# 3065ARPIRZ register map
File version: 1.0
Registers are 32-bit, access per field, reset 0x0 unless marked. A register's access mark holds for its fields unless they carry their own. Offsets are from the block's base; [hi:lo] are bit positions.

## IOCMG_ANA — IOCMG_ANA peripheral interface
Base 0x149F0000
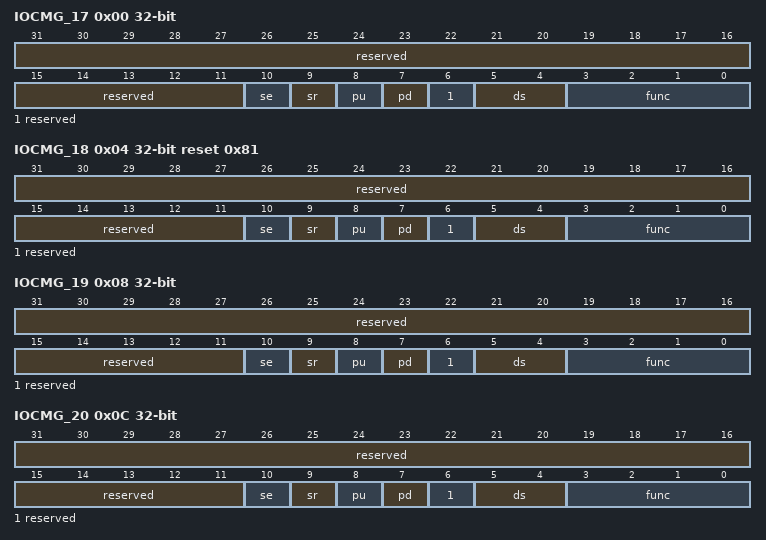
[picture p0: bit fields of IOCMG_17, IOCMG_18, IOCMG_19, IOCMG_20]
0x00 IOCMG_17 — QDM_INDEX/POE1 管脚配置寄存器。
  [31:11] reserved ro — 保留。
  [10] se rw — 管脚施密特输入控制。 0x0：关闭； 0x1：打开。
  [9] sr rw — 管脚电平转换速率控制。 0x0：快沿输出； 0x1：慢沿输出。
  [8] pu rw — 管脚上拉控制。 0x0：关闭； 0x1：打开。
  [7] pd rw — 管脚下拉控制。 0x0：关闭； 0x1：打开。
  [6] reserved ro — 保留。
  [5:4] ds rw — 管脚驱动能力选择（档位越大，驱动能力越大）。 00：档位4； 01：档位3； 10：档位2； 11：档位1。
  [3:0] func rw — 功能选择。 0x0: GPIO1_6； 0x1: QDM_INDEX； 0x2: POE1； 0x3: QDM_SYNC； 其它: 保留。
0x04 IOCMG_18 reset 0x81 — TRSTN/ADC1_B3/CAPM1 管脚配置寄存器。
  [31:11] reserved ro — 保留。
  [10] se rw — 管脚施密特输入控制。 0x0：关闭； 0x1：打开。
  [9] sr rw — 管脚电平转换速率控制。 0x0：快沿输出； 0x1：慢沿输出。
  [8] pu rw — 管脚上拉控制。 0x0：关闭； 0x1：打开。
  [7] pd rw — 管脚下拉控制： 0x0：关闭； 0x1：打开。
  [6] reserved ro — 保留。
  [5:4] ds rw — 管脚驱动能力选择（档位越大，驱动能力越大）。 00：档位4； 01：档位3； 10：档位2； 11：档位1。
  [3:0] func rw — 功能选择。 0x0: GPIO1_7； 0x1: JTAG_TRSTN； 0x3: CAPM1_SRC1； 0x4: UART1_CTSN； 0x5: SPI0_CSN0； 0x6: ADTRG1； 0x8: ADC1_ANA_B3； 0x9: ACMP1_ANA_N2； 其它: 保留。
0x08 IOCMG_19 — ADC1_B4/CAPM2 管脚配置寄存器。
  [31:11] reserved ro — 保留。
  [10] se rw — 管脚施密特输入控制。 0x0：关闭； 0x1：打开。
  [9] sr rw — 管脚电平转换速率控制。 0x0：快沿输出； 0x1：慢沿输出。
  [8] pu rw — 管脚上拉控制。 0x0：关闭； 0x1：打开。
  [7] pd rw — 管脚下拉控制。 0x0：关闭； 0x1：打开。
  [6] reserved ro — 保留。
  [5:4] ds rw — 管脚驱动能力选择（档位越大，驱动能力越大）。 00：档位4； 01：档位3； 10：档位2； 11：档位1。
  [3:0] func rw — 功能选择。 0x0: GPIO2_0； 0x3: CAPM2_SRC1； 0x5: SPI0_TXD； 0x8: ADC1_ANA_B4； 其它: 保留。
0x0C IOCMG_20 — ADC1_B5 管脚配置寄存器。
  [31:11] reserved ro — 保留。
  [10] se rw — 管脚施密特输入控制。 0x0：关闭； 0x1：打开。
  [9] sr rw — 管脚电平转换速率控制。 0x0：快沿输出； 0x1：慢沿输出。
  [8] pu rw — 管脚上拉控制。 0x0：关闭； 0x1：打开。
  [7] pd rw — 管脚下拉控制。 0x0：关闭； 0x1：打开。
  [6] reserved ro — 保留。
  [5:4] ds rw — 管脚驱动能力选择（档位越大，驱动能力越大）。 00：档位4； 01：档位3； 10：档位2； 11：档位1。
  [3:0] func rw — 功能选择。 0x0: GPIO2_1； 0x3: CAPM0_SRC1； 0x5: SPI0_RXD； 0x8: ADC1_ANA_B5； 其它: 保留。
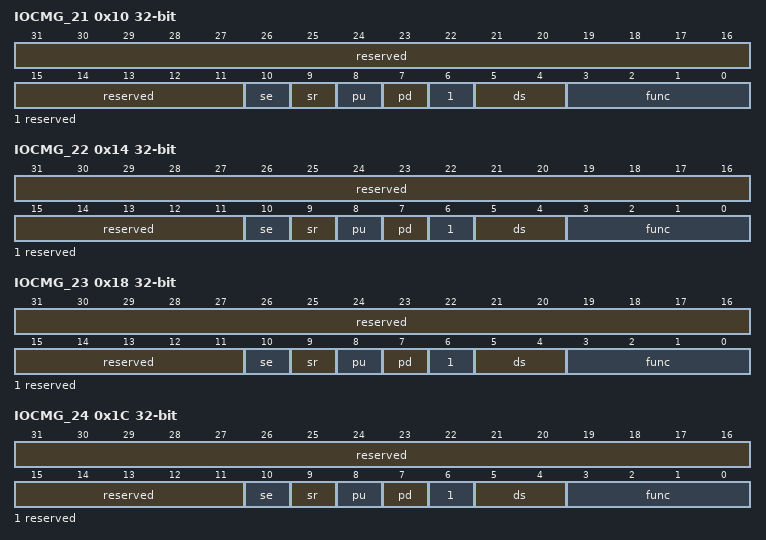
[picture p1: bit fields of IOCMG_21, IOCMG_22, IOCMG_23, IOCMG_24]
0x10 IOCMG_21 — ADC1_A1 管脚配置寄存器。
  [31:11] reserved ro — 保留。
  [10] se rw — 管脚施密特输入控制。 0x0：关闭； 0x1：打开。
  [9] sr rw — 管脚电平转换速率控制。 0x0：快沿输出； 0x1：慢沿输出。
  [8] pu rw — 管脚上拉控制。 0x0：关闭； 0x1：打开。
  [7] pd rw — 管脚下拉控制。 0x0：关闭； 0x1：打开。
  [6] reserved ro — 保留。
  [5:4] ds rw — 管脚驱动能力选择（档位越大，驱动能力越大）。 00：档位4； 01：档位3； 10：档位2； 11：档位1。
  [3:0] func rw — 功能选择。 0x0: GPIO2_2； 0x2: APT_EVTMP4； 0x4: UART1_RTSN； 0x5: SPI0_CSN1； 0x6: ADST1； 0x8: ADC1_ANA_A1； 0x9: ACMP1_ANA_P2； 其它: 保留。
0x14 IOCMG_22 — ADC1_A2/PGA1IN_P0 管脚配置寄存器。
  [31:11] reserved ro — 保留。
  [10] se rw — 管脚施密特输入控制。 0x0：关闭； 0x1：打开。
  [9] sr rw — 管脚电平转换速率控制。 0x0：快沿输出； 0x1：慢沿输出。
  [8] pu rw — 管脚上拉控制。 0x0：关闭； 0x1：打开。
  [7] pd rw — 管脚下拉控制。 0x0：关闭； 0x1：打开。
  [6] reserved ro — 保留。
  [5:4] ds rw — 管脚驱动能力选择（档位越大，驱动能力越大）。 00：档位4； 01：档位3； 10：档位2； 11：档位1。
  [3:0] func rw — 功能选择。 0x0: GPIO2_3； 0x5: SPI0_CLK； 0x8: ADC1_ANA_A2； 0x9: PGA1_ANA_P0； 其它: 保留。
0x18 IOCMG_23 — ADC1_B2/PGA1IN_N0/APT6_A 管脚配置寄存器。
  [31:11] reserved ro — 保留。
  [10] se rw — 管脚施密特输入控制。 0x0：关闭； 0x1：打开。
  [9] sr rw — 管脚电平转换速率控制。 0x0：快沿输出； 0x1：慢沿输出。
  [8] pu rw — 管脚上拉控制。 0x0：关闭； 0x1：打开。
  [7] pd rw — 管脚下拉控制。 0x0：关闭； 0x1：打开。
  [6] reserved ro — 保留。
  [5:4] ds rw — 管脚驱动能力选择（档位越大，驱动能力越大）。 00：档位4； 01：档位3； 10：档位2； 11：档位1。
  [3:0] func rw — 功能选择。 0x0: GPIO2_4； 0x3: APT6_PWMA； 0x8: ADC1_ANA_B2； 0x9: PGA1_ANA_N0； 其它: 保留。
0x1C IOCMG_24 — PGA1OUT0 管脚配置寄存器。
  [31:11] reserved ro — 保留。
  [10] se rw — 管脚施密特输入控制。 0x0：关闭； 0x1：打开。
  [9] sr rw — 管脚电平转换速率控制。 0x0：快沿输出； 0x1：慢沿输出。
  [8] pu rw — 管脚上拉控制。 0x0：关闭； 0x1：打开。
  [7] pd rw — 管脚下拉控制。 0x0：关闭； 0x1：打开。
  [6] reserved ro — 保留。
  [5:4] ds rw — 管脚驱动能力选择（档位越大，驱动能力越大）。 00：档位4； 01：档位3； 10：档位2； 11：档位1。
  [3:0] func rw — 功能选择。 0x0: GPIO2_5； 0x3: APT7_PWMA； 0x8: PGA1_ANA_EXT0； 其它: 保留。
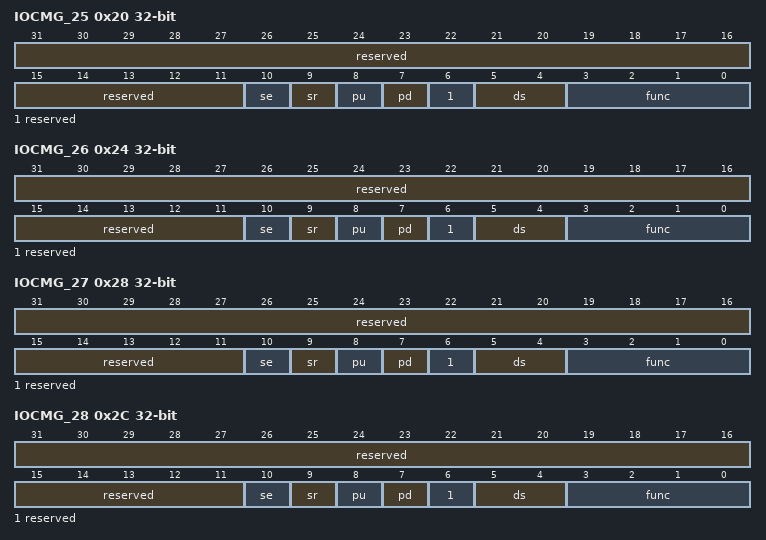
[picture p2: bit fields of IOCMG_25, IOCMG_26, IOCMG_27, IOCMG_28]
0x20 IOCMG_25 — ADC1_A3 管脚配置寄存器。
  [31:11] reserved ro — 保留。
  [10] se rw — 管脚施密特输入控制。 0x0：关闭； 0x1：打开。
  [9] sr rw — 管脚电平转换速率控制。 0x0：快沿输出； 0x1：慢沿输出。
  [8] pu rw — 管脚上拉控制。 0x0：关闭； 0x1：打开。
  [7] pd rw — 管脚下拉控制。 0x0：关闭； 0x1：打开。
  [6] reserved ro — 保留。
  [5:4] ds rw — 管脚驱动能力选择（档位越大，驱动能力越大）。 00：档位4； 01：档位3； 10：档位2； 11：档位1。
  [3:0] func rw — 功能选择。 0x0: GPIO2_6； 0x3: APT8_PWMA； 0x4: POE0； 0x6: ADST0； 0x8: ADC1_ANA_A3； 其它: 保留。
0x24 IOCMG_26 — ADC1_A4/APT6_B 管脚配置寄存器。
  [31:11] reserved ro — 保留。
  [10] se rw — 管脚施密特输入控制。 0x0：关闭； 0x1：打开。
  [9] sr rw — 管脚电平转换速率控制。 0x0：快沿输出； 0x1：慢沿输出。
  [8] pu rw — 管脚上拉控制。 0x0：关闭； 0x1：打开。
  [7] pd rw — 管脚下拉控制。 0x0：关闭； 0x1：打开。
  [6] reserved ro — 保留。
  [5:4] ds rw — 管脚驱动能力选择（档位越大，驱动能力越大）。 00：档位4； 01：档位3； 10：档位2； 11：档位1。
  [3:0] func rw — 功能选择。 0x0: GPIO2_7； 0x2: ACMP1_OUT； 0x3: APT6_PWMB； 0x8: ADC1_ANA_A4； 其它: 保留。
0x28 IOCMG_27 — ADC1_A5/APT7_B 管脚配置寄存器。
  [31:11] reserved ro — 保留。
  [10] se rw — 管脚施密特输入控制。 0x0：关闭； 0x1：打开。
  [9] sr rw — 管脚电平转换速率控制。 0x0：快沿输出； 0x1：慢沿输出。
  [8] pu rw — 管脚上拉控制。 0x0：关闭； 0x1：打开。
  [7] pd rw — 管脚下拉控制。 0x0：关闭； 0x1：打开。
  [6] reserved ro — 保留。
  [5:4] ds rw — 管脚驱动能力选择（档位越大，驱动能力越大）。 00：档位4； 01：档位3； 10：档位2； 11：档位1。
  [3:0] func rw — 功能选择。 0x0: GPIO3_0； 0x3: APT7_PWMB； 0x8: ADC1_ANA_A5； 0x9: ACMP1_ANA_N3； 其它: 保留。
0x2C IOCMG_28 — ADC1_A6/APT8_B 管脚配置寄存器。
  [31:11] reserved ro — 保留。
  [10] se rw — 管脚施密特输入控制。 0x0：关闭； 0x1：打开。
  [9] sr rw — 管脚电平转换速率控制。 0x0：快沿输出； 0x1：慢沿输出。
  [8] pu rw — 管脚上拉控制。 0x0：关闭； 0x1：打开。
  [7] pd rw — 管脚下拉控制。 0x0：关闭； 0x1：打开。
  [6] reserved ro — 保留。
  [5:4] ds rw — 管脚驱动能力选择（档位越大，驱动能力越大）。 00：档位4； 01：档位3； 10：档位2； 11：档位1。
  [3:0] func rw — 功能选择。 0x0: GPIO3_1； 0x3: APT8_PWMB； 0x8: ADC1_ANA_A6； 0x9: ACMP1_ANA_P3； 其它: 保留。
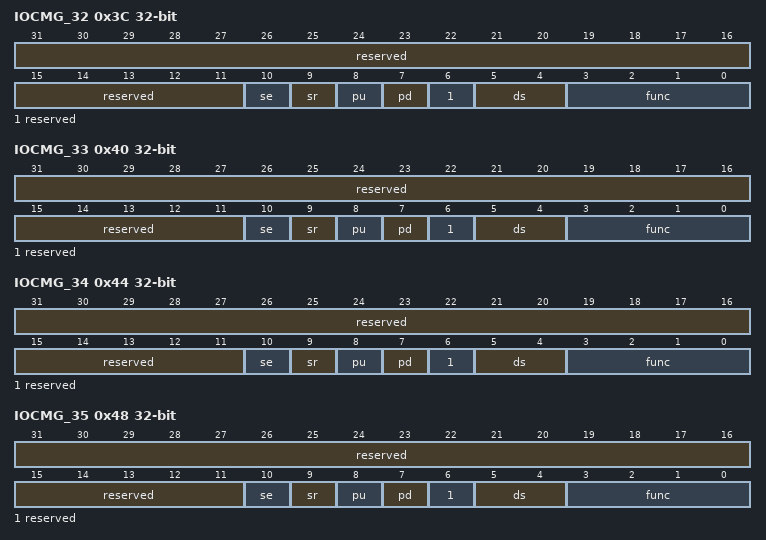
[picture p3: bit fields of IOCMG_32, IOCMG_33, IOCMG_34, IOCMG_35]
0x3C IOCMG_32 — APT0_A 管脚配置寄存器。
  [31:11] reserved ro — 保留。
  [10] se rw — 管脚施密特输入控制。 0x0：关闭； 0x1：打开。
  [9] sr rw — 管脚电平转换速率控制。 0x0：快沿输出； 0x1：慢沿输出。
  [8] pu rw — 管脚上拉控制。 0x0：关闭； 0x1：打开。
  [7] pd rw — 管脚下拉控制。 0x0：关闭； 0x1：打开。
  [6] reserved ro — 保留。
  [5:4] ds rw — 管脚驱动能力选择（档位越大，驱动能力越大）。 00：档位4； 01：档位3； 10：档位2； 11：档位1。
  [3:0] func rw — 功能选择。 0x0: GPIO3_5； 0x3: APT0_PWMA； 其它: 保留。
0x40 IOCMG_33 — APT1_A 管脚配置寄存器。
  [31:11] reserved ro — 保留。
  [10] se rw — 管脚施密特输入控制。 0x0：关闭； 0x1：打开。
  [9] sr rw — 管脚电平转换速率控制。 0x0：快沿输出； 0x1：慢沿输出。
  [8] pu rw — 管脚上拉控制。 0x0：关闭； 0x1：打开。
  [7] pd rw — 管脚下拉控制。 0x0：关闭； 0x1：打开。
  [6] reserved ro — 保留。
  [5:4] ds rw — 管脚驱动能力选择（档位越大，驱动能力越大）。 00：档位4； 01：档位3； 10：档位2； 11：档位1。
  [3:0] func rw — 功能选择。 0x0: GPIO3_6； 0x3: APT1_PWMA； 0x8: DAC0_ANA_OUT； 其它: 保留。
0x44 IOCMG_34 — APT2_A 管脚配置寄存器。
  [31:11] reserved ro — 保留。
  [10] se rw — 管脚施密特输入控制。 0x0：关闭； 0x1：打开。
  [9] sr rw — 管脚电平转换速率控制。 0x0：快沿输出； 0x1：慢沿输出。
  [8] pu rw — 管脚上拉控制。 0x0：关闭； 0x1：打开。
  [7] pd rw — 管脚下拉控制。 0x0：关闭； 0x1：打开。
  [6] reserved ro — 保留。
  [5:4] ds rw — 管脚驱动能力选择（档位越大，驱动能力越大）。 00：档位4； 01：档位3； 10：档位2； 11：档位1。
  [3:0] func rw — 功能选择。 0x0: GPIO3_7； 0x3: APT2_PWMA； 0x8: DAC1_ANA_OUT； 其它: 保留。
0x48 IOCMG_35 — APT0_B 管脚配置寄存器。
  [31:11] reserved ro — 保留。
  [10] se rw — 管脚施密特输入控制。 0x0：关闭； 0x1：打开。
  [9] sr rw — 管脚电平转换速率控制。 0x0：快沿输出； 0x1：慢沿输出。
  [8] pu rw — 管脚上拉控制。 0x0：关闭； 0x1：打开。
  [7] pd rw — 管脚下拉控制。 0x0：关闭； 0x1：打开。
  [6] reserved ro — 保留。
  [5:4] ds rw — 管脚驱动能力选择（档位越大，驱动能力越大）。 00：档位4； 01：档位3； 10：档位2； 11：档位1。
  [3:0] func rw — 功能选择。 0x0: GPIO4_0； 0x3: APT0_PWMB； 0x8: DAC2_ANA_OUT； 其它: 保留。
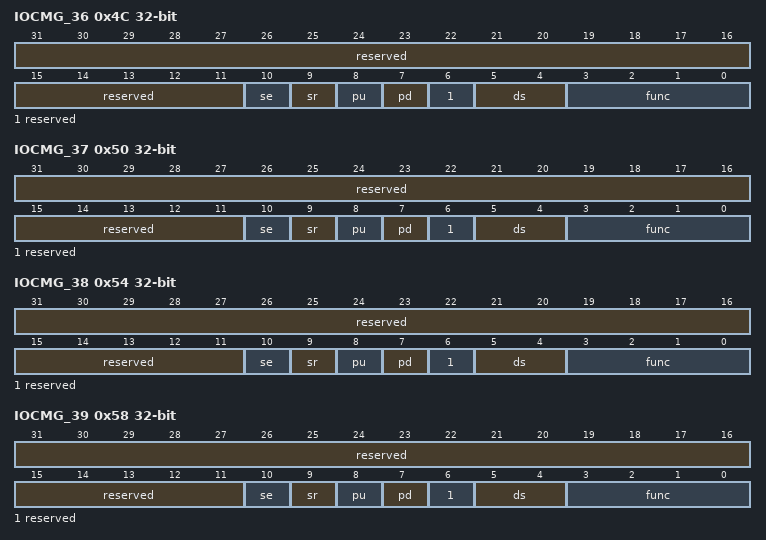
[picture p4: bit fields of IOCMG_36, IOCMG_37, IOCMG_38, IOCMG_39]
0x4C IOCMG_36 — APT1_B 管脚配置寄存器。
  [31:11] reserved ro — 保留。
  [10] se rw — 管脚施密特输入控制。 0x0：关闭； 0x1：打开。
  [9] sr rw — 管脚电平转换速率控制。 0x0：快沿输出； 0x1：慢沿输出。
  [8] pu rw — 管脚上拉控制。 0x0：关闭； 0x1：打开。
  [7] pd rw — 管脚下拉控制。 0x0：关闭； 0x1：打开。
  [6] reserved ro — 保留。
  [5:4] ds rw — 管脚驱动能力选择（档位越大，驱动能力越大）。 00：档位4； 01：档位3； 10：档位2； 11：档位1。
  [3:0] func rw — 功能选择。 0x0: GPIO4_1； 0x3: APT1_PWMB； 0x4: ADC_OB_CLK； 其它: 保留。
0x50 IOCMG_37 — APT2_B 管脚配置寄存器。
  [31:11] reserved ro — 保留。
  [10] se rw — 管脚施密特输入控制。 0x0：关闭； 0x1：打开。
  [9] sr rw — 管脚电平转换速率控制。 0x0：快沿输出； 0x1：慢沿输出。
  [8] pu rw — 管脚上拉控制。 0x0：关闭； 0x1：打开。
  [7] pd rw — 管脚下拉控制。 0x0：关闭； 0x1：打开。
  [6] reserved ro — 保留。
  [5:4] ds rw — 管脚驱动能力选择（档位越大，驱动能力越大）。 00：档位4； 01：档位3； 10：档位2； 11：档位1。
  [3:0] func rw — 功能选择。 0x0: GPIO4_2； 0x3: APT2_PWMB； 0x4: ADC_OB_DATA； 其它: 保留。
0x54 IOCMG_38 — PGA0IN_P0 管脚配置寄存器。
  [31:11] reserved ro — 保留。
  [10] se rw — 管脚施密特输入控制。 0x0：关闭； 0x1：打开。
  [9] sr rw — 管脚电平转换速率控制。 0x0：快沿输出； 0x1：慢沿输出。
  [8] pu rw — 管脚上拉控制。 0x0：关闭； 0x1：打开。
  [7] pd rw — 管脚下拉控制。 0x0：关闭； 0x1：打开。
  [6] reserved ro — 保留。
  [5:4] ds rw — 管脚驱动能力选择（档位越大，驱动能力越大）。 00：档位4； 01：档位3； 10：档位2； 11：档位1。
  [3:0] func rw — 功能选择。 0x0: GPIO4_3； 0x8: ADC0_ANA_A7； 0x9: PGA0_ANA_P0； 其它: 保留。
0x58 IOCMG_39 — PGA0IN_N0 管脚配置寄存器。
  [31:11] reserved ro — 保留。
  [10] se rw — 管脚施密特输入控制。 0x0：关闭； 0x1：打开。
  [9] sr rw — 管脚电平转换速率控制。 0x0：快沿输出； 0x1：慢沿输出。
  [8] pu rw — 管脚上拉控制。 0x0：关闭； 0x1：打开。
  [7] pd rw — 管脚下拉控制。 0x0：关闭； 0x1：打开。
  [6] reserved ro — 保留。
  [5:4] ds rw — 管脚驱动能力选择（档位越大，驱动能力越大）。 00：档位4； 01：档位3； 10：档位2； 11：档位1。
  [3:0] func rw — 功能选择。 0x0: GPIO4_4； 0x8: ADC0_ANA_B0； 0x9: PGA0_ANA_N0； 其它: 保留。
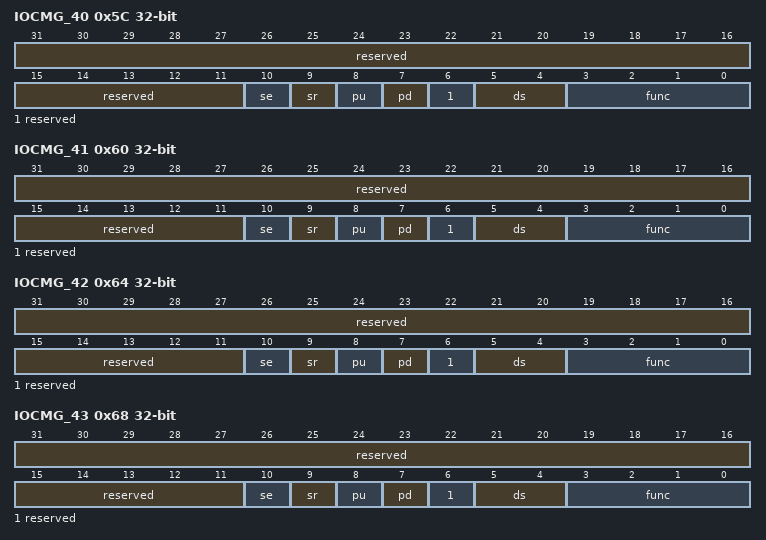
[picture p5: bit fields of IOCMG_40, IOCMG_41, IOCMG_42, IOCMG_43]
0x5C IOCMG_40 — PGA0OUT 管脚配置寄存器。
  [31:11] reserved ro — 保留。
  [10] se rw — 管脚施密特输入控制。 0x0：关闭； 0x1：打开。
  [9] sr rw — 管脚电平转换速率控制。 0x0：快沿输出； 0x1：慢沿输出。
  [8] pu rw — 管脚上拉控制。 0x0：关闭； 0x1：打开。
  [7] pd rw — 管脚下拉控制。 0x0：关闭； 0x1：打开。
  [6] reserved ro — 保留。
  [5:4] ds rw — 管脚驱动能力选择（档位越大，驱动能力越大）。 00：档位4； 01：档位3； 10：档位2； 11：档位1。
  [3:0] func rw — 功能选择。 0x0: GPIO4_5； 0x8: PGA0_ANA_EXT0； 其它: 保留。
0x60 IOCMG_41 — GPIO4_6 管脚配置寄存器。
  [31:11] reserved ro — 保留。
  [10] se rw — 管脚施密特输入控制。 0x0：关闭； 0x1：打开。
  [9] sr rw — 管脚电平转换速率控制。 0x0：快沿输出； 0x1：慢沿输出。
  [8] pu rw — 管脚上拉控制。 0x0：关闭； 0x1：打开。
  [7] pd rw — 管脚下拉控制。 0x0：关闭； 0x1：打开。
  [6] reserved ro — 保留。
  [5:4] ds rw — 管脚驱动能力选择（档位越大，驱动能力越大）。 00：档位4； 01：档位3； 10：档位2； 11：档位1。
  [3:0] func rw — 功能选择。 0x0: GPIO4_6； 0x6: ADTRG0； 0x8: ADC0_ANA_A3； 0x9: PGA1_ANA_P3； 其它: 保留。
0x64 IOCMG_42 — GPIO4_7 管脚配置寄存器。
  [31:11] reserved ro — 保留。
  [10] se rw — 管脚施密特输入控制。 0x0：关闭； 0x1：打开。
  [9] sr rw — 管脚电平转换速率控制。 0x0：快沿输出； 0x1：慢沿输出。
  [8] pu rw — 管脚上拉控制。 0x0：关闭； 0x1：打开。
  [7] pd rw — 管脚下拉控制。 0x0：关闭； 0x1：打开。
  [6] reserved ro — 保留。
  [5:4] ds rw — 管脚驱动能力选择（档位越大，驱动能力越大）。 00：档位4； 01：档位3； 10：档位2； 11：档位1。
  [3:0] func rw — 功能选择。 0x0: GPIO4_7； 0x8: ADC0_ANA_A4； 0x9: PGA1_ANA_N3； 0xa: ACMP0_ANA_N1； 其它: 保留。
0x68 IOCMG_43 — GPIO5_0/POE0 管脚配置寄存器。
  [31:11] reserved ro — 保留。
  [10] se rw — 管脚施密特输入控制。 0x0：关闭； 0x1：打开。
  [9] sr rw — 管脚电平转换速率控制。 0x0：快沿输出； 0x1：慢沿输出。
  [8] pu rw — 管脚上拉控制。 0x0：关闭； 0x1：打开。
  [7] pd rw — 管脚下拉控制。 0x0：关闭； 0x1：打开。
  [6] reserved ro — 保留。
  [5:4] ds rw — 管脚驱动能力选择（档位越大，驱动能力越大）。 00：档位4； 01：档位3； 10：档位2； 11：档位1。
  [3:0] func rw — 功能选择。 0x0: GPIO5_0； 0x2: ACMP0_OUT； 0x3: APT_EVTMP4； 0x4: POE0； 0x6: ADST0； 0x9: PGA1_ANA_EXT0； 其它: 保留。
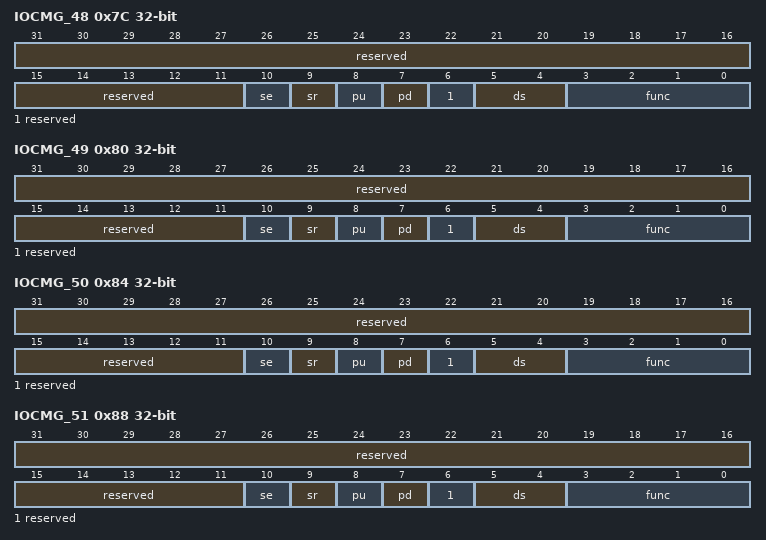
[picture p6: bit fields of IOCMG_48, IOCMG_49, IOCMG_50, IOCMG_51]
0x7C IOCMG_48 — GPIO5_5 管脚配置寄存器。
  [31:11] reserved ro — 保留。
  [10] se rw — 管脚施密特输入控制。 0x0：关闭； 0x1：打开。
  [9] sr rw — 管脚电平转换速率控制。 0x0：快沿输出； 0x1：慢沿输出。
  [8] pu rw — 管脚上拉控制。 0x0：关闭； 0x1：打开。
  [7] pd rw — 管脚下拉控制。 0x0：关闭； 0x1：打开。
  [6] reserved ro — 保留。
  [5:4] ds rw — 管脚驱动能力选择（档位越大，驱动能力越大）。 00：档位4； 01：档位3； 10：档位2； 11：档位1。
  [3:0] func rw — 功能选择。 0x0: GPIO5_5； 0x1: SYS_RSTN_OUT； 0x8: ADC2_ANA_B1； 0x9: PGA2_ANA_P0； 其它: 保留。
0x80 IOCMG_49 — GPIO5_6 管脚配置寄存器。
  [31:11] reserved ro — 保留。
  [10] se rw — 管脚施密特输入控制。 0x0：关闭； 0x1：打开。
  [9] sr rw — 管脚电平转换速率控制。 0x0：快沿输出； 0x1：慢沿输出。
  [8] pu rw — 管脚上拉控制。 0x0：关闭； 0x1：打开。
  [7] pd rw — 管脚下拉控制。 0x0：关闭； 0x1：打开。
  [6] reserved ro — 保留。
  [5:4] ds rw — 管脚驱动能力选择（档位越大，驱动能力越大）。 00：档位4； 01：档位3； 10：档位2； 11：档位1。
  [3:0] func rw — 功能选择。 0x0: GPIO5_6； 0x8: ADC2_ANA_A6； 0x9: PGA2_ANA_N0； 其它: 保留。
0x84 IOCMG_50 — GPIO5_7 管脚配置寄存器。
  [31:11] reserved ro — 保留。
  [10] se rw — 管脚施密特输入控制。 0x0：关闭； 0x1：打开。
  [9] sr rw — 管脚电平转换速率控制。 0x0：快沿输出； 0x1：慢沿输出。
  [8] pu rw — 管脚上拉控制。 0x0：关闭； 0x1：打开。
  [7] pd rw — 管脚下拉控制。 0x0：关闭； 0x1：打开。
  [6] reserved ro — 保留。
  [5:4] ds rw — 管脚驱动能力选择（档位越大，驱动能力越大）。 00：档位4； 01：档位3； 10：档位2； 11：档位1。
  [3:0] func rw — 功能选择。 0x0: GPIO5_7； 0x9: PGA2_ANA_EXT0； 其它: 保留。
0x88 IOCMG_51 — ADC2_A7 管脚配置寄存器。
  [31:11] reserved ro — 保留。
  [10] se rw — 管脚施密特输入控制。 0x0：关闭； 0x1：打开。
  [9] sr rw — 管脚电平转换速率控制。 0x0：快沿输出； 0x1：慢沿输出。
  [8] pu rw — 管脚上拉控制。 0x0：关闭； 0x1：打开。
  [7] pd rw — 管脚下拉控制。 0x0：关闭； 0x1：打开。
  [6] reserved ro — 保留。
  [5:4] ds rw — 管脚驱动能力选择（档位越大，驱动能力越大）。 00：档位4； 01：档位3； 10：档位2； 11：档位1。
  [3:0] func rw — 功能选择。 0x0: GPIO6_0； 0x3: UART2_TXD； 0x8: ADC2_ANA_A7； 0x9: ACMP2_ANA_N1； 其它: 保留。
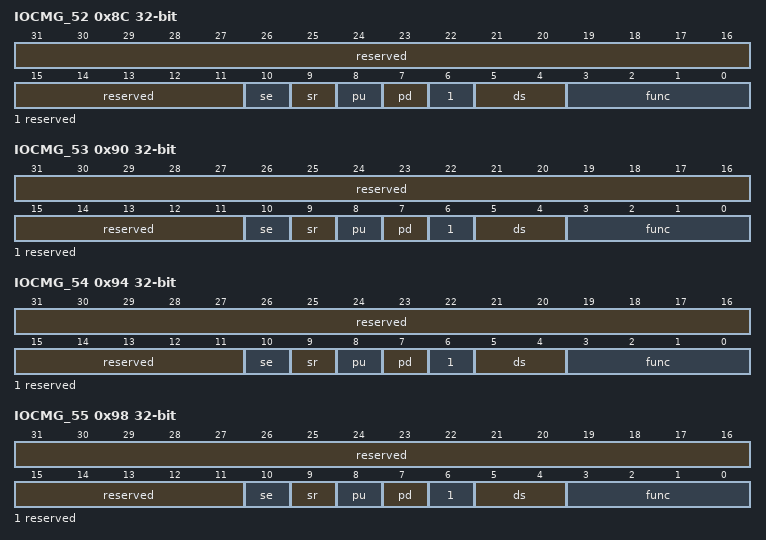
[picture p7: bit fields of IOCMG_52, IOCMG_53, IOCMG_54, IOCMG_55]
0x8C IOCMG_52 — ADC2_B0 管脚配置寄存器。
  [31:11] reserved ro — 保留。
  [10] se rw — 管脚施密特输入控制。 0x0：关闭； 0x1：打开。
  [9] sr rw — 管脚电平转换速率控制。 0x0：快沿输出； 0x1：慢沿输出。
  [8] pu rw — 管脚上拉控制。 0x0：关闭； 0x1：打开。
  [7] pd rw — 管脚下拉控制。 0x0：关闭； 0x1：打开。
  [6] reserved ro — 保留。
  [5:4] ds rw — 管脚驱动能力选择（档位越大，驱动能力越大）。 00：档位4； 01：档位3； 10：档位2； 11：档位1。
  [3:0] func rw — 功能选择。 0x0: GPIO6_1； 0x3: UART2_RXD； 0x8: ADC2_ANA_B0； 0x9: ACMP2_ANA_P1； 其它: 保留。
0x90 IOCMG_53 — ADC2_A1 管脚配置寄存器。
  [31:11] reserved ro — 保留。
  [10] se rw — 管脚施密特输入控制。 0x0：关闭； 0x1：打开。
  [9] sr rw — 管脚电平转换速率控制。 0x0：快沿输出； 0x1：慢沿输出。
  [8] pu rw — 管脚上拉控制。 0x0：关闭； 0x1：打开。
  [7] pd rw — 管脚下拉控制。 0x0：关闭； 0x1：打开。
  [6] reserved ro — 保留。
  [5:4] ds rw — 管脚驱动能力选择（档位越大，驱动能力越大）。 00：档位4； 01：档位3； 10：档位2； 11：档位1。
  [3:0] func rw — 功能选择。 0x0: GPIO6_2； 0x2: ACMP2_OUT； 0x6: ADST2； 0x8: ADC2_ANA_A1； 其它: 保留。
0x94 IOCMG_54 — ADC2_A2/POE2 管脚配置寄存器。
  [31:11] reserved ro — 保留。
  [10] se rw — 管脚施密特输入控制。 0x0：关闭； 0x1：打开。
  [9] sr rw — 管脚电平转换速率控制。 0x0：快沿输出； 0x1：慢沿输出。
  [8] pu rw — 管脚上拉控制。 0x0：关闭； 0x1：打开。
  [7] pd rw — 管脚下拉控制。 0x0：关闭； 0x1：打开。
  [6] reserved ro — 保留。
  [5:4] ds rw — 管脚驱动能力选择（档位越大，驱动能力越大）。 00：档位4； 01：档位3； 10：档位2； 11：档位1。
  [3:0] func rw — 功能选择。 0x0: GPIO6_3； 0x2: POE2； 0x3: CAN_RX； 0x6: ADTRG2； 0x8: ADC2_ANA_A2； 其它: 保留。
0x98 IOCMG_55 — ADC2_B2 管脚配置寄存器。
  [31:11] reserved ro — 保留。
  [10] se rw — 管脚施密特输入控制。 0x0：关闭； 0x1：打开。
  [9] sr rw — 管脚电平转换速率控制。 0x0：快沿输出； 0x1：慢沿输出。
  [8] pu rw — 管脚上拉控制。 0x0：关闭； 0x1：打开。
  [7] pd rw — 管脚下拉控制。 0x0：关闭； 0x1：打开。
  [6] reserved ro — 保留。
  [5:4] ds rw — 管脚驱动能力选择（档位越大，驱动能力越大）。 00：档位4； 01：档位3； 10：档位2； 11：档位1。
  [3:0] func rw — 功能选择。 0x0: GPIO6_4； 0x2: APT_EVTMP6； 0x3: CAN_TX； 0x8: ADC2_ANA_B2； 其它: 保留。
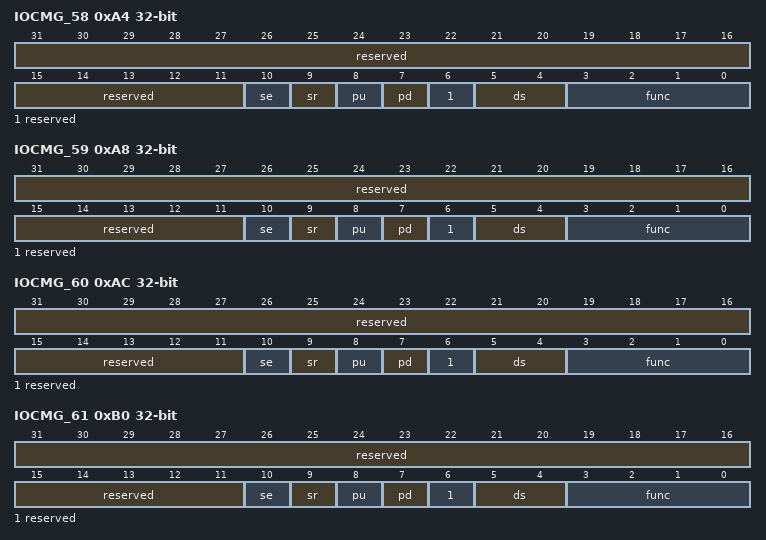
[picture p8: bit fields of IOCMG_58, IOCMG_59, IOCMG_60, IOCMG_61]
0xA4 IOCMG_58 — APT3_A 管脚配置寄存器。
  [31:11] reserved ro — 保留。
  [10] se rw — 管脚施密特输入控制。 0x0：关闭； 0x1：打开。
  [9] sr rw — 管脚电平转换速率控制。 0x0：快沿输出； 0x1：慢沿输出。
  [8] pu rw — 管脚上拉控制。 0x0：关闭； 0x1：打开。
  [7] pd rw — 管脚下拉控制。 0x0：关闭； 0x1：打开。
  [6] reserved ro — 保留。
  [5:4] ds rw — 管脚驱动能力选择（档位越大，驱动能力越大）。 00：档位4； 01：档位3； 10：档位2； 11：档位1。
  [3:0] func rw — 功能选择。 0x0: GPIO6_7； 0x1: APT3_PWMA； 其它: 保留。
0xA8 IOCMG_59 — APT4_A 管脚配置寄存器。
  [31:11] reserved ro — 保留。
  [10] se rw — 管脚施密特输入控制。 0x0：关闭； 0x1：打开。
  [9] sr rw — 管脚电平转换速率控制。 0x0：快沿输出； 0x1：慢沿输出。
  [8] pu rw — 管脚上拉控制。 0x0：关闭； 0x1：打开。
  [7] pd rw — 管脚下拉控制。 0x0：关闭； 0x1：打开。
  [6] reserved ro — 保留。
  [5:4] ds rw — 管脚驱动能力选择（档位越大，驱动能力越大）。 00：档位4； 01：档位3； 10：档位2； 11：档位1。
  [3:0] func rw — 功能选择。 0x0: GPIO7_0； 0x1: APT4_PWMA； 其它: 保留。
0xAC IOCMG_60 — APT5_A 管脚配置寄存器。
  [31:11] reserved ro — 保留。
  [10] se rw — 管脚施密特输入控制。 0x0：关闭； 0x1：打开。
  [9] sr rw — 管脚电平转换速率控制。 0x0：快沿输出； 0x1：慢沿输出。
  [8] pu rw — 管脚上拉控制。 0x0：关闭； 0x1：打开。
  [7] pd rw — 管脚下拉控制。 0x0：关闭； 0x1：打开。
  [6] reserved ro — 保留。
  [5:4] ds rw — 管脚驱动能力选择（档位越大，驱动能力越大）。 00：档位4； 01：档位3； 10：档位2； 11：档位1。
  [3:0] func rw — 功能选择。 0x0: GPIO7_1； 0x1: APT5_PWMA； 其它: 保留。
0xB0 IOCMG_61 — APT3_B 管脚配置寄存器。
  [31:11] reserved ro — 保留。
  [10] se rw — 管脚施密特输入控制。 0x0：关闭； 0x1：打开。
  [9] sr rw — 管脚电平转换速率控制。 0x0：快沿输出； 0x1：慢沿输出。
  [8] pu rw — 管脚上拉控制。 0x0：关闭； 0x1：打开。
  [7] pd rw — 管脚下拉控制。 0x0：关闭； 0x1：打开。
  [6] reserved ro — 保留。
  [5:4] ds rw — 管脚驱动能力选择（档位越大，驱动能力越大）。 00：档位4； 01：档位3； 10：档位2； 11：档位1。
  [3:0] func rw — 功能选择。 0x0: GPIO7_2； 0x1: APT3_PWMB； 其它: 保留。
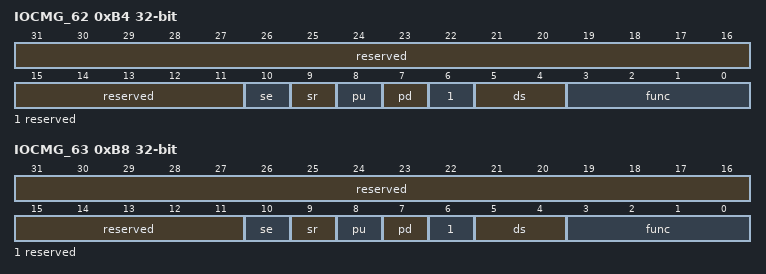
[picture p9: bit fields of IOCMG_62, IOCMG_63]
0xB4 IOCMG_62 — APT4_B 管脚配置寄存器。
  [31:11] reserved ro — 保留。
  [10] se rw — 管脚施密特输入控制。 0x0：关闭； 0x1：打开。
  [9] sr rw — 管脚电平转换速率控制。 0x0：快沿输出； 0x1：慢沿输出。
  [8] pu rw — 管脚上拉控制。 0x0：关闭； 0x1：打开。
  [7] pd rw — 管脚下拉控制。 0x0：关闭； 0x1：打开。
  [6] reserved ro — 保留。
  [5:4] ds rw — 管脚驱动能力选择（档位越大，驱动能力越大）。 00：档位4； 01：档位3； 10：档位2； 11：档位1。
  [3:0] func rw — 功能选择。 0x0: GPIO7_3； 0x1: APT4_PWMB； 其它: 保留。
0xB8 IOCMG_63 — APT5_B 管脚配置寄存器。
  [31:11] reserved ro — 保留。
  [10] se rw — 管脚施密特输入控制。 0x0：关闭； 0x1：打开。
  [9] sr rw — 管脚电平转换速率控制。 0x0：快沿输出； 0x1：慢沿输出。
  [8] pu rw — 管脚上拉控制。 0x0：关闭； 0x1：打开。
  [7] pd rw — 管脚下拉控制。 0x0：关闭； 0x1：打开。
  [6] reserved ro — 保留。
  [5:4] ds rw — 管脚驱动能力选择（档位越大，驱动能力越大）。 00：档位4； 01：档位3； 10：档位2； 11：档位1。
  [3:0] func rw — 功能选择。 0x0: GPIO7_4； 0x1: APT5_PWMB； 其它: 保留。
